# ESP32-C3 register map
Vendor: ESPRESSIF SYSTEMS (SHANGHAI) CO., LTD.; Series: ESP32-C3; File version: 8
CPU: RV32IMC r0p0, little endian, no MPU, no FPU, 4 interrupt priority bits
Address unit: 32 bits
Registers are 32-bit, read-write, reset 0x0 unless marked. A register's access mark holds for its fields unless they carry their own. Offsets are from the block's base; [hi:lo] are bit positions; {n}, {i} and the like mark numbered series.

## DS — Digital Signature
Base 0x6003D000
{0x0+i} Y_MEM[{i}] (i=0..511) 8-bit access not given — memory that stores Y
{0x200+i} M_MEM[{i}] (i=0..511) 8-bit access not given — memory that stores M
{0x400+i} RB_MEM[{i}] (i=0..511) 8-bit access not given — memory that stores Rb
{0x600+i} BOX_MEM[{i}] (i=0..47) 8-bit access not given — memory that stores BOX
{0x800+i} X_MEM[{i}] (i=0..511) 8-bit access not given — memory that stores X
{0xA00+i} Z_MEM[{i}] (i=0..511) 8-bit access not given — memory that stores Z
0xE00 SET_START wo — DS start control register
  [0] SET_START — set this bit to start DS operation.
0xE04 SET_CONTINUE wo — DS continue control register
  [0] SET_CONTINUE — set this bit to continue DS operation.
0xE08 SET_FINISH wo — DS finish control register
  [0] SET_FINISH — Set this bit to finish DS process.
0xE0C QUERY_BUSY ro — DS query busy register
  [0] QUERY_BUSY — digital signature state. 1'b0: idle, 1'b1: busy
0xE10 QUERY_KEY_WRONG ro — DS query key-wrong counter register
  [3:0] QUERY_KEY_WRONG — digital signature key wrong counter
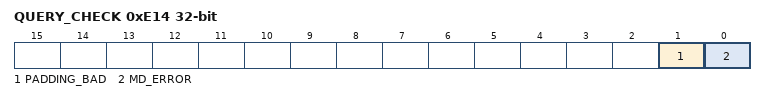
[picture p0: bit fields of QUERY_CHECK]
0xE14 QUERY_CHECK ro — DS query check result register
  [1] PADDING_BAD — padding checkout result. 1'b0: a good padding, 1'b1: a bad padding
  [0] MD_ERROR — MD checkout result. 1'b0: MD check pass, 1'b1: MD check fail
0xE20 DATE reset 0x20200618 — DS version control register
  [29:0] DATE — ds version information

## GPIOSD — Sigma-Delta Modulation
Base 0x60004F00
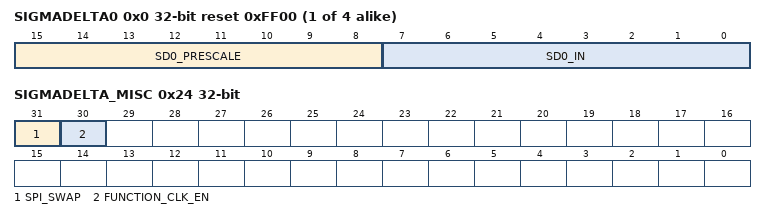
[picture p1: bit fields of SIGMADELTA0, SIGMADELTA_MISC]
{0x0+4i} SIGMADELTA{i} (i=0..3) reset 0xFF00 — Duty Cycle Configure Register of SDM{i}
  [15:8] SD0_PRESCALE — This field is used to set a divider value to divide APB clock.
  [7:0] SD0_IN — This field is used to configure the duty cycle of sigma delta modulation output.
0x20 SIGMADELTA_CG — Clock Gating Configure Register
  [31] CLK_EN — Clock enable bit of configuration registers for sigma delta modulation.
0x24 SIGMADELTA_MISC — MISC Register
  [31] SPI_SWAP — Reserved.
  [30] FUNCTION_CLK_EN — Clock enable bit of sigma delta modulation.
0x28 SIGMADELTA_VERSION reset 0x2006230 — Version Control Register
  [27:0] GPIO_SD_DATE — Version control register.

## HMAC — HMAC (Hash-based Message Authentication Code) Accelerator
Base 0x6003E000
0x40 SET_START wo — Process control register 0.
  [0] SET_START — Start hmac operation.
0x44 SET_PARA_PURPOSE wo — Configure purpose.
  [3:0] PURPOSE_SET — Set hmac parameter purpose.
0x48 SET_PARA_KEY wo — Configure key.
  [2:0] KEY_SET — Set hmac parameter key.
0x4C SET_PARA_FINISH wo — Finish initial configuration.
  [0] SET_PARA_END — Finish hmac configuration.
0x50 SET_MESSAGE_ONE wo — Process control register 1.
  [0] SET_TEXT_ONE — Call SHA to calculate one message block.
0x54 SET_MESSAGE_ING wo — Process control register 2.
  [0] SET_TEXT_ING — Continue typical hmac.
0x58 SET_MESSAGE_END wo — Process control register 3.
  [0] SET_TEXT_END — Start hardware padding.
0x5C SET_RESULT_FINISH wo — Process control register 4.
  [0] SET_RESULT_END — After read result from upstream, then let hmac back to idle.
0x60 SET_INVALIDATE_JTAG wo — Invalidate register 0.
  [0] SET_INVALIDATE_JTAG — Clear result from hmac downstream JTAG.
0x64 SET_INVALIDATE_DS wo — Invalidate register 1.
  [0] SET_INVALIDATE_DS — Clear result from hmac downstream DS.
0x68 QUERY_ERROR ro — Error register.
  [0] QUREY_CHECK — Hmac configuration state. 0: key are agree with purpose. 1: error
0x6C QUERY_BUSY ro — Busy register.
  [0] BUSY_STATE — Hmac state. 1'b0: idle. 1'b1: busy
{0x80+i} WR_MESSAGE_MEM[{i}] (i=0..63) 8-bit access not given — Message block memory.
{0xC0+i} RD_RESULT_MEM[{i}] (i=0..31) 8-bit access not given — Result from upstream.
0xF0 SET_MESSAGE_PAD wo — Process control register 5.
  [0] SET_TEXT_PAD — Start software padding.
0xF4 ONE_BLOCK wo — Process control register 6.
  [0] SET_ONE_BLOCK — Don't have to do padding.
0xF8 SOFT_JTAG_CTRL wo — Jtag register 0.
  [0] SOFT_JTAG_CTRL — Turn on JTAG verification.
0xFC WR_JTAG wo — Jtag register 1.
  [31:0] WR_JTAG — 32-bit of key to be compared.
